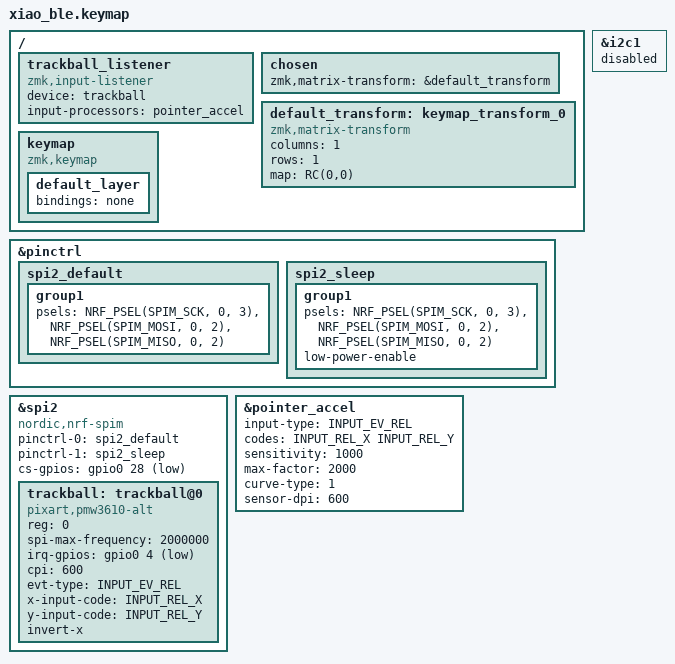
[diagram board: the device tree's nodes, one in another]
/*
 * Standalone PMW3610 trackball on Xiao BLE, no shield.
 *
 * Wiring (Xiao pin -> PMW3610-PCB pin):
 *   D0 -> SDIO   D1 -> SCLK   D2 -> NCS   D3 -> NRESET   D4 -> MOT
 *
 * badjeff's driver talks SPI, not raw bit-banged GPIO: SCLK/SDIO/NCS map to
 * a real SPI bus (SDIO is wired to a single physical line, but MOSI and
 * MISO are both routed to that same pin in pinctrl below since the sensor
 * only has one bidirectional data line). MOT is the motion/irq line.
 *
 * D3/NRESET is not wired up in software: the current driver has no
 * reset-gpios property at all. It's tied directly to 3.3V in hardware
 * instead of relying on the PMW3610's internal weak pull-up alone, which
 * turned out to not be reliable enough on this build.
 *
 * D4/D5 are xiao_ble's default I2C1 (SDA/SCL) pins, and the board enables
 * i2c1 out of the box. That would have stolen D4 away from MOT, so i2c1
 * must be disabled below to free both pins for plain GPIO use.
 */

#include <zephyr/dt-bindings/pinctrl/nrf-pinctrl.h>
#include <zephyr/dt-bindings/gpio/gpio.h>
#include <zephyr/dt-bindings/input/input-event-codes.h>
#include <behaviors.dtsi>
#include <dt-bindings/zmk/keys.h>
#include <dt-bindings/zmk/matrix_transform.h>
#include <input/processors.dtsi>
#include <behaviors/input_gestures_accel.dtsi>

&i2c1 {
    status = "disabled";
};

&pinctrl {
    spi2_default: spi2_default {
        group1 {
            psels = <NRF_PSEL(SPIM_SCK, 0, 3)>,
                    <NRF_PSEL(SPIM_MOSI, 0, 2)>,
                    <NRF_PSEL(SPIM_MISO, 0, 2)>;
        };
    };

    spi2_sleep: spi2_sleep {
        group1 {
            psels = <NRF_PSEL(SPIM_SCK, 0, 3)>,
                    <NRF_PSEL(SPIM_MOSI, 0, 2)>,
                    <NRF_PSEL(SPIM_MISO, 0, 2)>;
            low-power-enable;
        };
    };
};

&spi2 {
    compatible = "nordic,nrf-spim";
    status = "okay";
    pinctrl-0 = <&spi2_default>;
    pinctrl-1 = <&spi2_sleep>;
    pinctrl-names = "default", "sleep";
    cs-gpios = <&gpio0 28 GPIO_ACTIVE_LOW>; /* D2 = NCS */

    trackball: trackball@0 {
        compatible = "pixart,pmw3610-alt";
        status = "okay";
        reg = <0>;
        spi-max-frequency = <2000000>;
        irq-gpios = <&gpio0 4 (GPIO_ACTIVE_LOW | GPIO_PULL_UP)>; /* D4 = MOT */

        cpi = <600>;
        evt-type = <INPUT_EV_REL>;
        x-input-code = <INPUT_REL_X>;
        y-input-code = <INPUT_REL_Y>;

        /* Uncomment to further adjust cursor orientation if needed: */
        // swap-xy;
        invert-x;
        // invert-y;
    };
};

&pointer_accel {
    input-type = <INPUT_EV_REL>;
    codes = <INPUT_REL_X INPUT_REL_Y>;
    sensitivity = <1000>;  /* 1.0x base speed - unchanged */
    max-factor = <2000>;   /* 2.0x max speed boost at high velocity */
    curve-type = <1>;      /* Mild curve */
    sensor-dpi = <600>;    /* matches cpi = <600> on &trackball above */
};

/ {
    trackball_listener: trackball_listener {
        compatible = "zmk,input-listener";
        device = <&trackball>;
        input-processors = <&pointer_accel>;
    };

    /* No physical keys exist, but ZMK still needs a matrix transform to
     * know the keymap size - this declares a single, unwired position. */
    chosen {
        zmk,matrix-transform = &default_transform;
    };

    default_transform: keymap_transform_0 {
        compatible = "zmk,matrix-transform";
        columns = <1>;
        rows = <1>;
        map = <RC(0,0)>;
    };

    keymap {
        compatible = "zmk,keymap";

        /* No physical buttons wired up - this default layer just holds a
         * placeholder for the single position declared above. */
        default_layer {
            bindings = <&none>;
        };
    };
};
